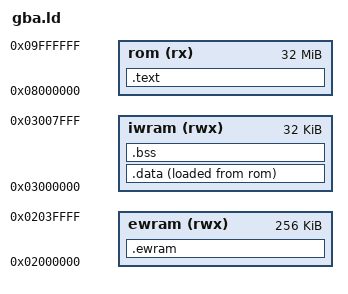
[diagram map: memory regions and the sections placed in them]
/* GBA cartridge linker script */
OUTPUT_FORMAT("elf32-littlearm")
OUTPUT_ARCH(arm)
ENTRY(_start)

MEMORY
{
    rom   (rx)  : ORIGIN = 0x08000000, LENGTH = 32M
    iwram (rwx) : ORIGIN = 0x03000000, LENGTH = 32K
    ewram (rwx) : ORIGIN = 0x02000000, LENGTH = 256K
}

SECTIONS
{
    .text :
    {
        KEEP(*(.crt0))
        *(.text*)
        *(.rodata*)
        . = ALIGN(4);
    } > rom

    .data : ALIGN(4)
    {
        __data_start = .;
        *(.data*)
        . = ALIGN(4);
        __data_end = .;
    } > iwram AT> rom
    __data_lma = LOADADDR(.data);

    .bss (NOLOAD) : ALIGN(4)
    {
        __bss_start = .;
        *(.bss*)
        *(COMMON)
        . = ALIGN(4);
        __bss_end = .;
    } > iwram

    .ewram (NOLOAD) : ALIGN(4)
    {
        __ewram_start = .;
        *(.ewram*)
        . = ALIGN(4);
        __ewram_end = .;
    } > ewram

    /DISCARD/ : { *(.ARM.exidx*) *(.ARM.attributes) *(.comment) }
}
